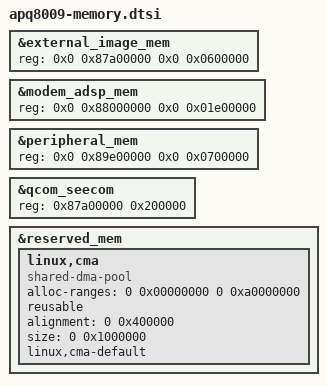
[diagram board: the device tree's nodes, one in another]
/*
 * Copyright (c) 2016, 2018 The Linux Foundation. All rights reserved.
 *
 * This program is free software; you can redistribute it and/or modify
 * it under the terms of the GNU General Public License version 2 and
 * only version 2 as published by the Free Software Foundation.
 *
 * This program is distributed in the hope that it will be useful,
 * but WITHOUT ANY WARRANTY; without even the implied warranty of
 * MERCHANTABILITY or FITNESS FOR A PARTICULAR PURPOSE.  See the
 * GNU General Public License for more details.
 */

&external_image_mem {
	reg = <0x0 0x87a00000 0x0 0x0600000>;
};

&modem_adsp_mem {
	reg = <0x0 0x88000000 0x0 0x01e00000>;
};

&peripheral_mem {
	reg = <0x0 0x89e00000 0x0 0x0700000>;
};

&qcom_seecom {
	reg = <0x87a00000 0x200000>;
};

&reserved_mem {
	linux,cma {
		compatible = "shared-dma-pool";
		alloc-ranges = <0 0x00000000 0 0xa0000000>;
		reusable;
		alignment = <0 0x400000>;
		size = <0 0x1000000>;
		linux,cma-default;
	};
};
